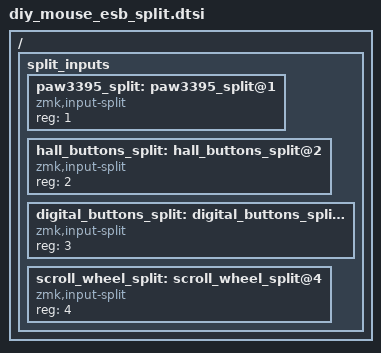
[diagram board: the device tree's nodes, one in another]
/ {
    split_inputs {
        #address-cells = <1>;
        #size-cells = <0>;

        paw3395_split: paw3395_split@1 {
            compatible = "zmk,input-split";
            reg = <1>;
        };

        hall_buttons_split: hall_buttons_split@2 {
            compatible = "zmk,input-split";
            reg = <2>;
        };

        digital_buttons_split: digital_buttons_split@3 {
            compatible = "zmk,input-split";
            reg = <3>;
        };

        scroll_wheel_split: scroll_wheel_split@4 {
            compatible = "zmk,input-split";
            reg = <4>;
        };
    };
};
